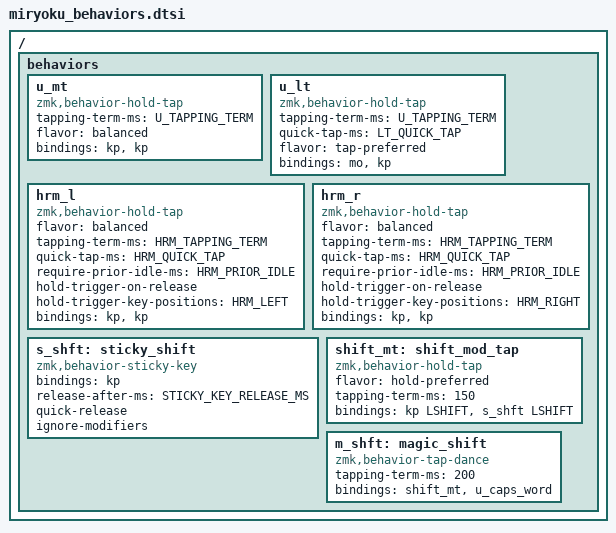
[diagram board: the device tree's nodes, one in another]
// Copyright 2022 Manna Harbour
// https://github.com/manna-harbour/miryoku

/ {
  behaviors {
    u_mt: u_mt {
      compatible = "zmk,behavior-hold-tap";
      #binding-cells = <2>;
      tapping-term-ms = <U_TAPPING_TERM>;
      flavor = "balanced";
      bindings = <&kp>, <&kp>;
    };
    u_lt: u_lt {
      compatible = "zmk,behavior-hold-tap";
      #binding-cells = <2>;
      tapping-term-ms = <U_TAPPING_TERM>;
      quick-tap-ms = <LT_QUICK_TAP>;
      flavor = "tap-preferred";
      bindings = <&mo>, <&kp>;
    };

// Custom functions not part of base miryoku
    // Home row mods (left and right) - define variables in custom_config.h
    // HRM_LEFT and HRM_Right are defined in the shield mapping (e.g. totem.h )
    hrm_l: hrm_l{
      compatible = "zmk,behavior-hold-tap";
      #binding-cells = <2>;
      flavor = "balanced";
      tapping-term-ms = <HRM_TAPPING_TERM>;
      quick-tap-ms = <HRM_QUICK_TAP>;
      require-prior-idle-ms = <HRM_PRIOR_IDLE>;
      hold-trigger-on-release;
      hold-trigger-key-positions = <HRM_LEFT>;
      bindings = <&kp>, <&kp>;
    };
    hrm_r: hrm_r{
          compatible = "zmk,behavior-hold-tap";
          #binding-cells = <2>;
          flavor = "balanced";
          tapping-term-ms = <HRM_TAPPING_TERM>;
          quick-tap-ms = <HRM_QUICK_TAP>;
          require-prior-idle-ms = <HRM_PRIOR_IDLE>;
          hold-trigger-on-release;
          hold-trigger-key-positions = <HRM_RIGHT>;
          bindings = <&kp>, <&kp>;
        };

    // Triple function shift
    // Custom sticky key
    s_shft: sticky_shift {
      compatible = "zmk,behavior-sticky-key";
      #binding-cells = <1>;
      bindings = <&kp>;
      release-after-ms = <STICKY_KEY_RELEASE_MS>;
      quick-release;
      ignore-modifiers;
    };

    // Custom mod-tap gives sticky shift on tap, regular on hold
    shift_mt: shift_mod_tap {
      compatible = "zmk,behavior-hold-tap";
      #binding-cells = <2>;
      flavor = "hold-preferred";
      tapping-term-ms = <150>;
      bindings = <&kp LSHIFT>, <&s_shft LSHIFT>;
    };
    
    // Tap dance so double tap gives a capsword
    m_shft: magic_shift {
      compatible = "zmk,behavior-tap-dance";
      #binding-cells = <0>;
      tapping-term-ms = <200>;
      bindings = <&shift_mt>, <&u_caps_word>;
    };
  };
};
